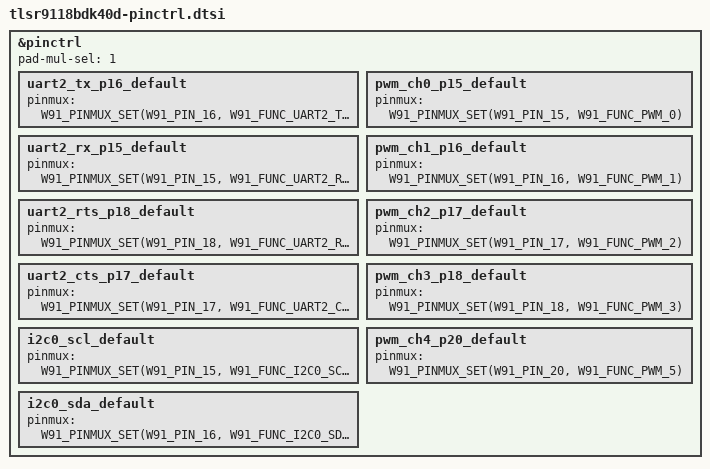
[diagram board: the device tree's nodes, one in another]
/*
 * Copyright (c) 2024 Telink Semiconductor
 *
 * SPDX-License-Identifier: Apache-2.0
 */

#include <zephyr/dt-bindings/pinctrl/w91-pinctrl.h>

&pinctrl {
	/* Set pad-mul-sel register value.
	 * Note: Pins functions below (pinmux = <...>) depend on this value.
	 */
	pad-mul-sel = <1>;

	/* UART2: TX(P16), RX(P15), RTS(P18), CTS(P17) */

	uart2_tx_p16_default: uart2_tx_p16_default {
		pinmux = <W91_PINMUX_SET(W91_PIN_16, W91_FUNC_UART2_TXD)>;
	};
	uart2_rx_p15_default: uart2_rx_p15_default {
		pinmux = <W91_PINMUX_SET(W91_PIN_15, W91_FUNC_UART2_RXD)>;
	};
	uart2_rts_p18_default: uart2_rts_p18_default {
		pinmux = <W91_PINMUX_SET(W91_PIN_18, W91_FUNC_UART2_RTS)>;
	};
	uart2_cts_p17_default: uart2_cts_p17_default {
		pinmux = <W91_PINMUX_SET(W91_PIN_17, W91_FUNC_UART2_CTS)>;
	};

	/* I2C0 */
	i2c0_scl_default: i2c0_scl_default {
		pinmux = <W91_PINMUX_SET(W91_PIN_15, W91_FUNC_I2C0_SCL)>;
	};
	i2c0_sda_default: i2c0_sda_default {
		pinmux = <W91_PINMUX_SET(W91_PIN_16, W91_FUNC_I2C0_SDA)>;
	};
	/* PWM Channel 0 (P15) */

	pwm_ch0_p15_default: pwm_ch0_p15_default {
		pinmux = <W91_PINMUX_SET(W91_PIN_15, W91_FUNC_PWM_0)>;
	};
	/* PWM Channel 1 (P16) */

	pwm_ch1_p16_default: pwm_ch1_p16_default {
		pinmux = <W91_PINMUX_SET(W91_PIN_16, W91_FUNC_PWM_1)>;
	};
	/* PWM Channel 2 (P17) */

	pwm_ch2_p17_default: pwm_ch2_p17_default {
		pinmux = <W91_PINMUX_SET(W91_PIN_17, W91_FUNC_PWM_2)>;
	};
	/* PWM Channel 3 (P18) */

	pwm_ch3_p18_default: pwm_ch3_p18_default {
		pinmux = <W91_PINMUX_SET(W91_PIN_18, W91_FUNC_PWM_3)>;
	};
	/* PWM Channel 4 (P20) */

	pwm_ch4_p20_default: pwm_ch4_p20_default {
		pinmux = <W91_PINMUX_SET(W91_PIN_20, W91_FUNC_PWM_5)>;
	};
};
